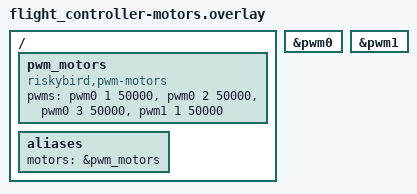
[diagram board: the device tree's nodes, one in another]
/*
 * Flight controller, Phase 4: adds the four motor outputs. PROPELLERS OFF, BATTERY REQUIRED.
 *
 * Declaring `motors` is what compiles the PWM actuator block in at all -- main.cpp guards it on
 * DT_NODE_EXISTS(DT_ALIAS(motors)) -- so every earlier phase is actuation-free by construction,
 * not by a runtime flag.
 */

#include "flight_controller-flow.overlay"

/ {
	/*
	 * Channel map from the harness binder (WithArty200TPWM in
	 * backends/chipyard/fpga/src/main/scala/arty200t/HarnessBinders.scala), which is the only
	 * authority on which comparator reaches which pin:
	 *
	 *   u[0] motor1  pwm0 cmp1  E22  J1_31
	 *   u[1] motor2  pwm0 cmp2  B20  J1_36
	 *   u[2] motor3  pwm0 cmp3  R17  J1_99
	 *   u[3] motor4  pwm1 cmp1  F13  J1_100
	 *
	 * Comparator 0 is absent on purpose: it sets the shared period and Zephyr's sifive driver
	 * refuses to drive it ("Channel 0 sets the period, we can't output PWM with it"), which is
	 * why four motors need two blocks.
	 *
	 * TWO CELLS, not three. The ESP board's LEDC binding takes <&ledc0 ch period flags>, but
	 * sifive,pwm0 declares "#pwm-cells" as const 2 -- <&pwm0 ch period> with no flags cell -- so
	 * the ESP specifiers cannot be transcribed directly.
	 *
	 * 50000 ns = 20 kHz, matching the ESP build. At the 50 MHz peripheral clock that is 2500
	 * cycles, well inside the 16-bit comparator, so pwmscale stays 0 and duty resolution is
	 * 1/2500 = 0.04%.
	 */
	pwm_motors: pwm_motors {
		compatible = "riskybird,pwm-motors";
		pwms = <&pwm0 1 50000>,
		       <&pwm0 2 50000>,
		       <&pwm0 3 50000>,
		       <&pwm1 1 50000>;
	};

	aliases {
		motors = &pwm_motors;
	};
};

&pwm0 {
	status = "okay";
};

&pwm1 {
	status = "okay";
};
